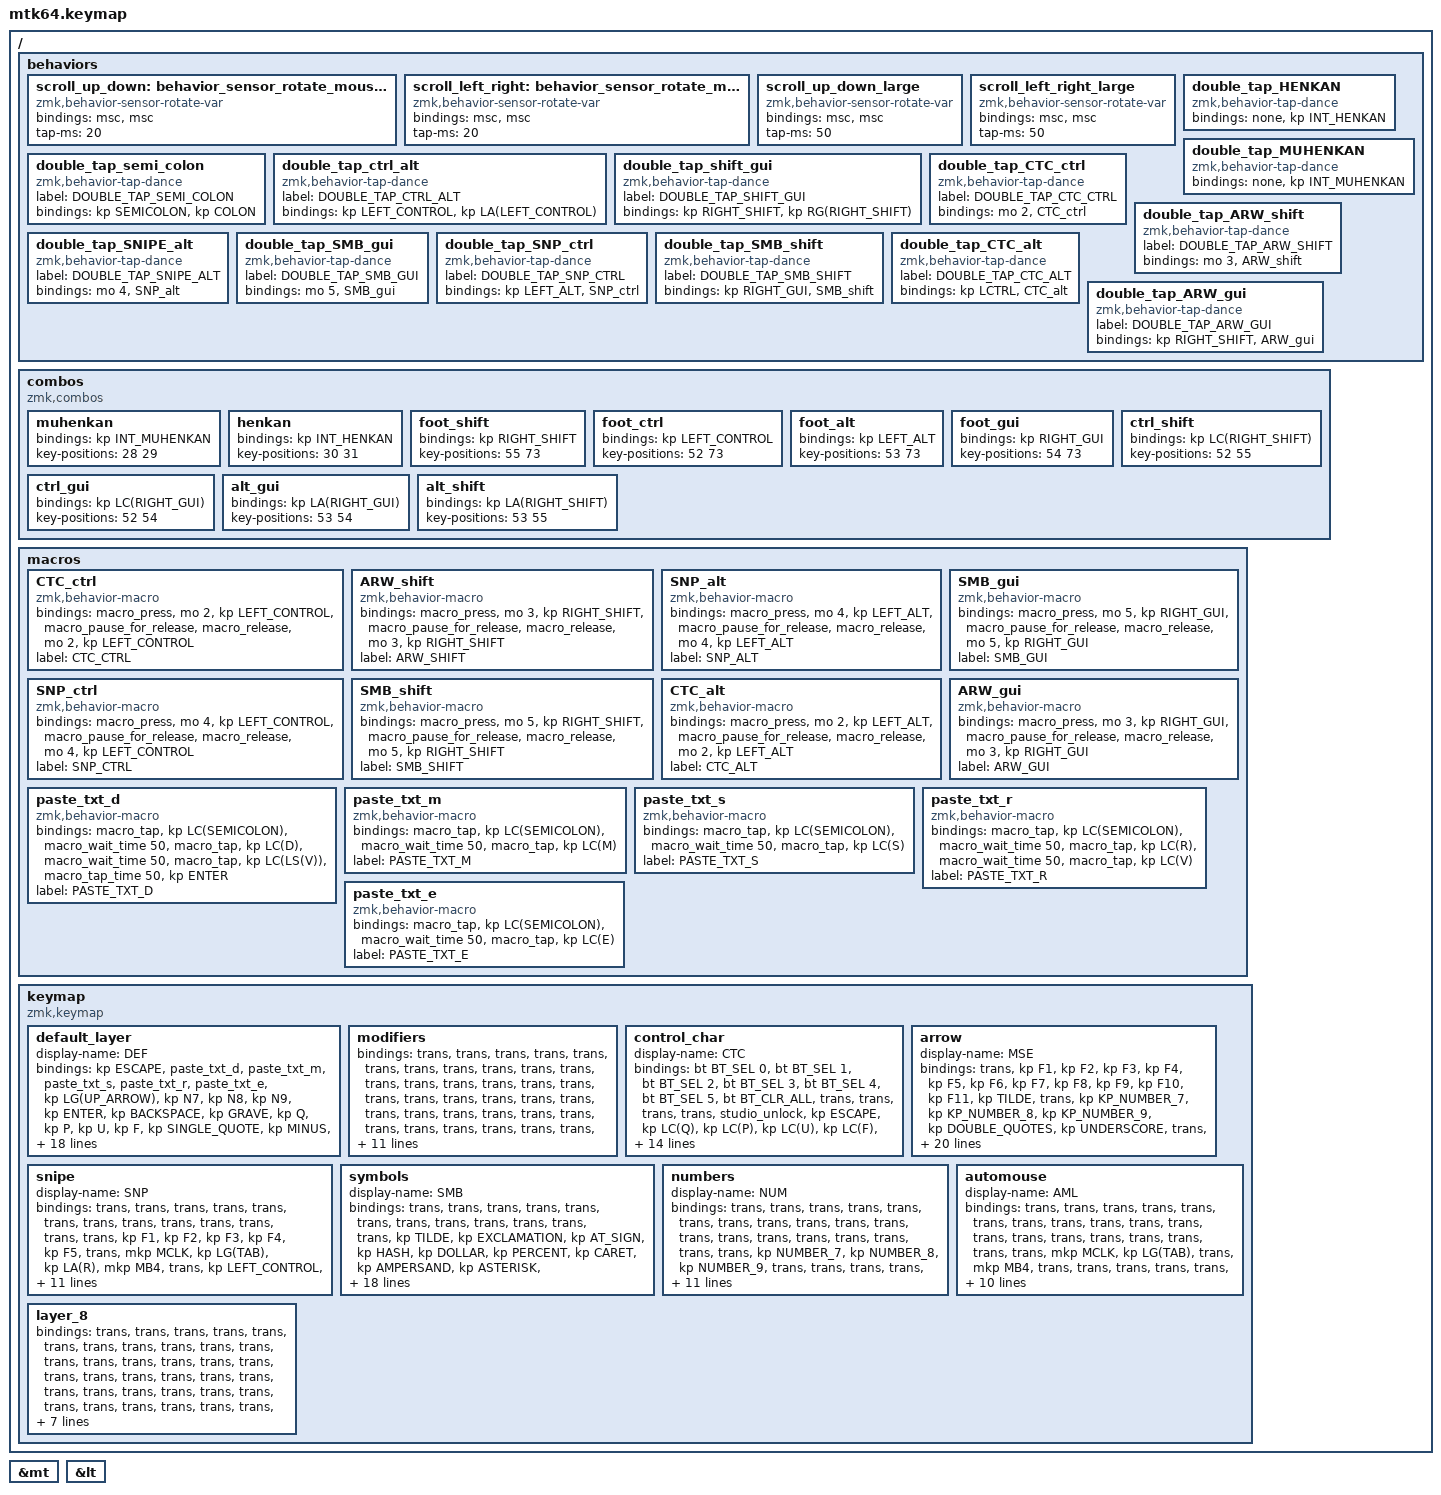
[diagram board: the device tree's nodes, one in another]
#include <input/processors.dtsi>
#include <behaviors.dtsi>
#include <dt-bindings/zmk/bt.h>
#include <dt-bindings/zmk/keys.h>
#include <dt-bindings/zmk/outputs.h>
#include <dt-bindings/zmk/pointing.h>
#include "keycode_japanese.h"

// スクロール量の設定

#define ZMK_POINTING_DEFAULT_SCRL_VAL 100

&mt {
};

&lt {
};

/* &mkp_input_listener { input-processors = <&zip_temp_layer 6 5000>; }; */

/ {
    behaviors {
        // 垂直スクロール用のbehaviorの設定

        scroll_up_down: behavior_sensor_rotate_mouse_wheel_up_down {
            compatible = "zmk,behavior-sensor-rotate-var";
            #sensor-binding-cells = <2>;
            bindings = <&msc>, <&msc>;

            tap-ms = <20>; // スクロールのタップ時間
        };

        // 水平スクロール用のbehaviorの設定

        scroll_left_right: behavior_sensor_rotate_mouse_wheel_left_right {
            compatible = "zmk,behavior-sensor-rotate-var";
            #sensor-binding-cells = <2>;
            bindings = <&msc>, <&msc>;

            tap-ms = <20>; // スクロールのタップ時間
        };

        scroll_up_down_large: scroll_up_down_large {
            compatible = "zmk,behavior-sensor-rotate-var";
            #sensor-binding-cells = <2>;
            bindings = <&msc>, <&msc>;

            tap-ms = <50>;
        };

        scroll_left_right_large: scroll_left_right_large {
            compatible = "zmk,behavior-sensor-rotate-var";
            #sensor-binding-cells = <2>;
            bindings = <&msc>, <&msc>;

            tap-ms = <50>;
        };

        double_tap_HENKAN: double_tap_HENKAN {
            compatible = "zmk,behavior-tap-dance";
            #binding-cells = <0>;
            bindings = <&none>, <&kp INT_HENKAN>;
        };

        double_tap_MUHENKAN: double_tap_MUHENKAN {
            compatible = "zmk,behavior-tap-dance";
            #binding-cells = <0>;
            bindings = <&none>, <&kp INT_MUHENKAN>;
        };

        double_tap_semi_colon: double_tap_semi_colon {
            compatible = "zmk,behavior-tap-dance";
            label = "DOUBLE_TAP_SEMI_COLON";
            #binding-cells = <0>;
            bindings = <&kp SEMICOLON>, <&kp COLON>;
        };

        // The same finger (Press the modifier keys on the same hand at the same time)

        double_tap_ctrl_alt: double_tap_ctrl_alt {
            compatible = "zmk,behavior-tap-dance";
            label = "DOUBLE_TAP_CTRL_ALT";
            #binding-cells = <0>;
            bindings = <&kp LEFT_CONTROL>, <&kp LA(LEFT_CONTROL)>;
        };

        // The same finger (Press the modifier keys on the same hand at the same time)

        double_tap_shift_gui: double_tap_shift_gui {
            compatible = "zmk,behavior-tap-dance";
            label = "DOUBLE_TAP_SHIFT_GUI";
            #binding-cells = <0>;
            bindings = <&kp RIGHT_SHIFT>, <&kp RG(RIGHT_SHIFT)>;
        };

        // The same key (Press the modifier key on the layer after moving)

        double_tap_CTC_ctrl: double_tap_CTC_ctrl {
            compatible = "zmk,behavior-tap-dance";
            label = "DOUBLE_TAP_CTC_CTRL";
            #binding-cells = <0>;
            bindings = <&mo 2>, <&CTC_ctrl>;
        };

        // The same key (Press the modifier key on the layer after moving)

        double_tap_ARW_shift: double_tap_ARW_shift {
            compatible = "zmk,behavior-tap-dance";
            label = "DOUBLE_TAP_ARW_SHIFT";
            #binding-cells = <0>;
            bindings = <&mo 3>, <&ARW_shift>;
        };

        // The same key (Press the modifier key on the layer after moving)

        double_tap_SNIPE_alt: double_tap_SNIPE_alt {
            compatible = "zmk,behavior-tap-dance";
            label = "DOUBLE_TAP_SNIPE_ALT";
            #binding-cells = <0>;
            bindings = <&mo 4>, <&SNP_alt>;
        };

        // The same key (Press the modifier key on the layer after moving)

        double_tap_SMB_gui: double_tap_SMB_gui {
            compatible = "zmk,behavior-tap-dance";
            label = "DOUBLE_TAP_SMB_GUI";
            #binding-cells = <0>;
            bindings = <&mo 5>, <&SMB_gui>;
        };

        // The same finger (Press the modifier key on the same hand after moving the layer)

        double_tap_SNP_ctrl: double_tap_SNP_ctrl {
            compatible = "zmk,behavior-tap-dance";
            label = "DOUBLE_TAP_SNP_CTRL";
            #binding-cells = <0>;
            bindings = <&kp LEFT_ALT>, <&SNP_ctrl>;
        };

        // The same finger (Press the modifier key on the same hand after moving the layer)

        double_tap_SMB_shift: double_tap_SMB_shift {
            compatible = "zmk,behavior-tap-dance";
            label = "DOUBLE_TAP_SMB_SHIFT";
            #binding-cells = <0>;
            bindings = <&kp RIGHT_GUI>, <&SMB_shift>;
        };

        // The same finger (Press the modifier key on the same hand after moving the layer)

        double_tap_CTC_alt: double_tap_CTC_alt {
            compatible = "zmk,behavior-tap-dance";
            label = "DOUBLE_TAP_CTC_ALT";
            #binding-cells = <0>;
            bindings = <&kp LCTRL>, <&CTC_alt>;
        };

        // The same finger (Press the modifier key on the same hand after moving the layer)

        double_tap_ARW_gui: double_tap_ARW_gui {
            compatible = "zmk,behavior-tap-dance";
            label = "DOUBLE_TAP_ARW_GUI";
            #binding-cells = <0>;
            bindings = <&kp RIGHT_SHIFT>, <&ARW_gui>;
        };
    };
};

/ {
    combos {
        compatible = "zmk,combos";

        muhenkan {
            bindings = <&kp INT_MUHENKAN>;
            key-positions = <28 29>;
        };

        henkan {
            bindings = <&kp INT_HENKAN>;
            key-positions = <30 31>;
        };

        foot_shift {
            bindings = <&kp RIGHT_SHIFT>;
            key-positions = <55 73>;
        };

        foot_ctrl {
            bindings = <&kp LEFT_CONTROL>;
            key-positions = <52 73>;
        };

        foot_alt {
            bindings = <&kp LEFT_ALT>;
            key-positions = <53 73>;
        };

        foot_gui {
            bindings = <&kp RIGHT_GUI>;
            key-positions = <54 73>;
        };

        ctrl_shift {
            bindings = <&kp LC(RIGHT_SHIFT)>;
            key-positions = <52 55>;
        };

        ctrl_gui {
            bindings = <&kp LC(RIGHT_GUI)>;
            key-positions = <52 54>;
        };

        alt_gui {
            bindings = <&kp LA(RIGHT_GUI)>;
            key-positions = <53 54>;
        };

        alt_shift {
            bindings = <&kp LA(RIGHT_SHIFT)>;
            key-positions = <53 55>;
        };
    };

    macros {
        CTC_ctrl: CTC_ctrl {
            compatible = "zmk,behavior-macro";
            #binding-cells = <0>;
            bindings =
                <&macro_press>,
                <&mo 2 &kp LEFT_CONTROL>,
                <&macro_pause_for_release>,
                <&macro_release>,
                <&mo 2 &kp LEFT_CONTROL>;

            label = "CTC_CTRL";
        };

        ARW_shift: ARW_shift {
            compatible = "zmk,behavior-macro";
            #binding-cells = <0>;
            bindings =
                <&macro_press>,
                <&mo 3 &kp RIGHT_SHIFT>,
                <&macro_pause_for_release>,
                <&macro_release>,
                <&mo 3 &kp RIGHT_SHIFT>;

            label = "ARW_SHIFT";
        };

        SNP_alt: SNP_alt {
            compatible = "zmk,behavior-macro";
            #binding-cells = <0>;
            bindings =
                <&macro_press>,
                <&mo 4 &kp LEFT_ALT>,
                <&macro_pause_for_release>,
                <&macro_release>,
                <&mo 4 &kp LEFT_ALT>;

            label = "SNP_ALT";
        };

        SMB_gui: SMB_gui {
            compatible = "zmk,behavior-macro";
            #binding-cells = <0>;
            bindings =
                <&macro_press>,
                <&mo 5 &kp RIGHT_GUI>,
                <&macro_pause_for_release>,
                <&macro_release>,
                <&mo 5 &kp RIGHT_GUI>;

            label = "SMB_GUI";
        };

        SNP_ctrl: SNP_ctrl {
            compatible = "zmk,behavior-macro";
            #binding-cells = <0>;
            bindings =
                <&macro_press>,
                <&mo 4 &kp LEFT_CONTROL>,
                <&macro_pause_for_release>,
                <&macro_release>,
                <&mo 4 &kp LEFT_CONTROL>;

            label = "SNP_CTRL";
        };

        SMB_shift: SMB_shift {
            compatible = "zmk,behavior-macro";
            #binding-cells = <0>;
            bindings =
                <&macro_press>,
                <&mo 5 &kp RIGHT_SHIFT>,
                <&macro_pause_for_release>,
                <&macro_release>,
                <&mo 5 &kp RIGHT_SHIFT>;

            label = "SMB_SHIFT";
        };

        CTC_alt: CTC_alt {
            compatible = "zmk,behavior-macro";
            #binding-cells = <0>;
            bindings =
                <&macro_press>,
                <&mo 2 &kp LEFT_ALT>,
                <&macro_pause_for_release>,
                <&macro_release>,
                <&mo 2 &kp LEFT_ALT>;

            label = "CTC_ALT";
        };

        ARW_gui: ARW_gui {
            compatible = "zmk,behavior-macro";
            #binding-cells = <0>;
            bindings =
                <&macro_press>,
                <&mo 3 &kp RIGHT_GUI>,
                <&macro_pause_for_release>,
                <&macro_release>,
                <&mo 3 &kp RIGHT_GUI>;

            label = "ARW_GUI";
        };

        paste_txt_d: paste_txt_d {
            compatible = "zmk,behavior-macro";
            #binding-cells = <0>;
            bindings =
                <&macro_tap>,
                <&kp LC(SEMICOLON)>,
                <&macro_wait_time 50>,
                <&macro_tap>,
                <&kp LC(D)>,
                <&macro_wait_time 50>,
                <&macro_tap>,
                <&kp LC(LS(V))>,
                <&macro_tap_time 50>,
                <&kp ENTER>;

            label = "PASTE_TXT_D";
        };

        paste_txt_m: paste_txt_m {
            compatible = "zmk,behavior-macro";
            #binding-cells = <0>;
            bindings =
                <&macro_tap>,
                <&kp LC(SEMICOLON)>,
                <&macro_wait_time 50>,
                <&macro_tap>,
                <&kp LC(M)>;

            label = "PASTE_TXT_M";
        };

        paste_txt_s: paste_txt_s {
            compatible = "zmk,behavior-macro";
            #binding-cells = <0>;
            bindings =
                <&macro_tap>,
                <&kp LC(SEMICOLON)>,
                <&macro_wait_time 50>,
                <&macro_tap>,
                <&kp LC(S)>;

            label = "PASTE_TXT_S";
        };

        paste_txt_r: paste_txt_r {
            compatible = "zmk,behavior-macro";
            #binding-cells = <0>;
            bindings =
                <&macro_tap>,
                <&kp LC(SEMICOLON)>,
                <&macro_wait_time 50>,
                <&macro_tap>,
                <&kp LC(R)>,
                <&macro_wait_time 50>,
                <&macro_tap>,
                <&kp LC(V)>;

            label = "PASTE_TXT_R";
        };

        paste_txt_e: paste_txt_e {
            compatible = "zmk,behavior-macro";
            #binding-cells = <0>;
            bindings =
                <&macro_tap>,
                <&kp LC(SEMICOLON)>,
                <&macro_wait_time 50>,
                <&macro_tap>,
                <&kp LC(E)>;

            label = "PASTE_TXT_E";
        };
    };

    keymap {
        compatible = "zmk,keymap";

        default_layer {
            display-name = "DEF";
            bindings = <
&kp ESCAPE      &paste_txt_d  &paste_txt_m  &paste_txt_s  &paste_txt_r  &paste_txt_e                                                                                                                                 &kp LG(UP_ARROW)  &kp N7  &kp N8  &kp N9  &kp ENTER  &kp BACKSPACE
&kp GRAVE       &kp Q         &kp P         &kp U         &kp F         &kp SINGLE_QUOTE                                                                                                                             &kp MINUS         &kp N   &kp S   &kp R   &kp Y      &kp UNDERSCORE
&kp SPACE       &kp E         &kp I         &kp A         &kp O         &double_tap_semi_colon                                                                                                                       &kp H             &kp J   &kp K   &kp L   &kp T      &kp B
&kp LEFT_SHIFT  &kp Z         &kp X         &kp C         &kp V         &kp COMMA               &kp LG(LEFT_ARROW)                                                                            &kp RG(RIGHT_ARROW)          &kp PERIOD        &kp D   &kp M   &kp G   &kp W      &kp RIGHT_SHIFT
&mo 1           &kp LGUI                                                                        &double_tap_CTC_ctrl  &double_tap_SNIPE_alt                            &double_tap_SMB_gui    &double_tap_ARW_shift                                            &mkp LCLK  &mkp RCLK
                                            &bt BT_PRV    &bt BT_NXT                                                  &kp LC(LEFT_ALT)                                 &kp RS(RIGHT_GUI)                                               &none   &none
                                                                                                                      &mo 5                                            &mo 5
                &mo 2         &mo 6         &mo 5                                                                                                                                                                                              &mo 2   &mo 6   &mo 5
                                                                                                                      &lt (1) LC(LG(LEFT_ARROW))   &lt (1) RG(RC(UP_ARROW))  &lt (1) LC(LG(RIGHT_ARROW))
            >;

            sensor-bindings =
                <&scroll_left_right SCRL_LEFT SCRL_RIGHT>,
                <&scroll_up_down SCRL_UP SCRL_DOWN>;
        };

        modifiers {
            bindings = <
&trans  &trans  &trans  &trans        &trans        &trans                                                                                                           &trans  &trans  &trans  &trans  &trans  &trans
&trans  &trans  &trans  &trans        &trans        &trans                                                                                                           &trans  &trans  &trans  &trans  &trans  &trans
&trans  &trans  &trans  &trans        &trans        &trans                                                                                                           &trans  &trans  &trans  &trans  &trans  &trans
&trans  &trans  &trans  &trans        &trans        &trans  &trans                                                                              &trans               &trans  &trans  &trans  &trans  &trans  &trans
&trans  &trans                                              &double_tap_CTC_alt  &double_tap_SNP_ctrl                    &double_tap_SMB_shift  &double_tap_ARW_gui                                  &trans  &trans
                        &out OUT_USB  &out OUT_BLE                               &trans                                  &trans                                              &trans  &trans
                                                                                 &trans                                  &trans
        &trans  &trans  &trans                                                                                                                                                       &trans  &trans  &trans
                                                                                 &kp LG(UP_ARROW)      &kp LG(UP_ARROW)  &kp RG(UP_ARROW)
            >;

            label = "MDF";
        };

        control_char {
            display-name = "CTC";
            bindings = <
&bt BT_SEL 0      &bt BT_SEL 1  &bt BT_SEL 2  &bt BT_SEL 3  &bt BT_SEL 4  &bt BT_SEL 5                                                                                                      &bt BT_CLR_ALL  &trans      &trans        &trans     &trans     &studio_unlock
&kp ESCAPE        &kp LC(Q)     &kp LC(P)     &kp LC(U)     &kp LC(F)     &trans                                                                                                            &trans          &kp LC(S)   &kp LC(N)     &kp LC(R)  &kp LC(Y)  &kp ESCAPE
&kp LEFT_CONTROL  &kp END       &kp TAB       &kp HOME      &kp LC(O)     &kp LC(SEMICOLON)                                                                                                 &kp BACKSPACE   &kp ENTER   &kp LC(K)     &kp LC(L)  &trans     &trans
&trans            &kp DELETE    &trans        &kp LC(C)     &kp LC(V)     &trans             &trans                                                                    &trans               &trans          &kp ESCAPE  &kp KP_ENTER  &trans     &kp LC(W)  &trans
&trans            &trans                                                                     &double_tap_CTC_alt  &double_tap_SNP_ctrl          &double_tap_SMB_shift  &double_tap_ARW_gui                                                       &trans     &trans
                                              &trans        &trans                                                &kp LS(LEFT_GUI)              &kp RC(RIGHT_ALT)                                           &trans      &trans
                                                                                                                  &trans                        &trans
                  &trans        &trans        &trans                                                                                                                                                                    &trans        &trans     &trans
                                                                                                                  &trans                &trans  &trans
            >;
        };

        arrow {
            display-name = "MSE";
            bindings = <
&trans     &kp F1                        &kp F2                      &kp F3                    &kp F4                    &kp F5                                                                                                            &kp F6          &kp F7          &kp F8        &kp F9           &kp F10          &kp F11
&kp TILDE  &trans                        &kp KP_NUMBER_7             &kp KP_NUMBER_8           &kp KP_NUMBER_9           &kp DOUBLE_QUOTES                                                                                                 &kp UNDERSCORE  &trans          &trans        &trans           &kp PRINTSCREEN  &kp F12
&trans     &trans                        &kp KP_NUMBER_4             &kp KP_NUMBER_5           &kp KP_NUMBER_6           &kp COLON                                                                                                         &kp LEFT_ARROW        &kp DOWN_ARROW  &kp UP_ARROW  &kp RIGHT_ARROW  &trans           &kp PRINTSCREEN
&trans     &mt LEFT_CONTROL KP_NUMBER_0  &mt LEFT_SHIFT KP_NUMBER_1  &mt LEFT_ALT KP_NUMBER_2  &mt LEFT_GUI KP_NUMBER_3  &trans             &trans                                                                    &trans               &trans          &trans          &trans        &trans           &trans           &trans
&trans     &trans                                                                                                                           &double_tap_CTC_alt  &double_tap_SNP_ctrl          &double_tap_SMB_shift  &double_tap_ARW_gui                                                                 &trans           &trans
                                                                     &trans                    &trans                                                            &kp LS(LEFT_GUI)              &kp RC(RIGHT_ALT)                                           &trans          &trans
                                                                                                                                                                 &trans                        &trans
           &trans                        &trans                      &trans                                                                                                                                                                                                &trans        &trans           &trans
                                                                                                                                                                 &trans                &trans  &trans
            >;

            sensor-bindings =
                <&inc_dec_kp LG(LS(TAB)) LG(TAB)>,
                <&inc_dec_kp LA(LS(TAB)) LA(TAB)>;
        };

        snipe {
            display-name = "SNP";
            bindings = <
&trans            &trans   &trans   &trans     &trans     &trans                                                                     &trans                  &trans     &trans       &trans                   &trans    &trans
&trans            &kp F1   &kp F2   &kp F3     &kp F4     &kp F5                                                                     &trans                  &mkp MCLK  &kp LG(TAB)  &kp LA(R)                &mkp MB4  &trans
&kp LEFT_CONTROL  &kp F6   &kp F7   &kp F8     &kp F9     &kp F10                                                                    &kp LC(LG(LEFT_ARROW))  &mkp LCLK  &mkp RCLK    &kp LC(LG(RIGHT_ARROW))  &trans    &trans
&kp LEFT_SHIFT    &kp F11  &kp F12  &kp LC(C)  &kp LC(V)  &trans   &trans                                           &trans           &mkp MB5                &mkp MB4   &trans       &trans                   &trans    &trans
&trans            &trans                                           &kp LEFT_CONTROL  &kp LEFT_ALT    &kp RIGHT_GUI  &kp RIGHT_SHIFT                                                                           &trans    &trans
            >;

            sensor-bindings =
                <&scroll_left_right_large SCRL_LEFT SCRL_RIGHT>,
                <&scroll_up_down_large SCRL_UP SCRL_DOWN>;
        };

        symbols {
            display-name = "SMB";
            bindings = <
&trans     &trans           &trans        &trans        &trans         &trans                                                                                &trans        &trans            &trans             &trans                &trans                 &trans
&kp TILDE  &kp EXCLAMATION  &kp AT_SIGN   &kp HASH      &kp DOLLAR     &kp PERCENT                                                                           &kp CARET     &kp AMPERSAND     &kp ASTERISK       &kp LEFT_PARENTHESIS  &kp RIGHT_PARENTHESIS  &trans
&kp EQUAL  &kp NUMBER_1     &kp NUMBER_2  &kp NUMBER_3  &kp NUMBER_4   &kp NUMBER_5                                                                          &kp NUMBER_6  &kp NUMBER_7      &kp NUMBER_8       &kp NUMBER_9          &kp NUMBER_0           &kp PLUS
&trans     &kp QUESTION     &kp PIPE      &kp SLASH     &kp BACKSLASH  &trans        &trans                                                 &trans           &trans        &kp LEFT_BRACKET  &kp RIGHT_BRACKET  &kp LEFT_BRACE        &kp RIGHT_BRACE        &trans
&trans     &trans                                                                    &kp LEFT_CONTROL  &kp LEFT_ALT          &kp RIGHT_GUI  &kp RIGHT_SHIFT                                                                           &trans                 &trans
                                          &out OUT_USB  &out OUT_BLE                                   &trans                &trans                                        &trans            &trans
                                                                                                       &trans                &trans
           &trans           &trans        &trans                                                                                                                                             &trans             &trans                &trans
                                                                                                       &trans        &trans  &trans
            >;

            sensor-bindings =
                <&inc_dec_kp C_VOLUME_UP C_VOLUME_DOWN>,
                <&inc_dec_kp PAGE_UP PAGE_DOWN>;
        };

        numbers {
            display-name = "NUM";
            bindings = <
&trans  &trans  &trans  &trans  &trans  &trans                                                                          &trans        &trans        &trans        &trans        &trans  &trans
&trans  &trans  &trans  &trans  &trans  &trans                                                                          &trans        &kp NUMBER_7  &kp NUMBER_8  &kp NUMBER_9  &trans  &trans
&trans  &trans  &trans  &trans  &trans  &trans                                                                          &kp PERIOD    &kp NUMBER_4  &kp NUMBER_5  &kp NUMBER_6  &trans  &trans
&trans  &trans  &trans  &trans  &trans  &trans  &trans                                                 &tog 6           &kp NUMBER_0  &kp NUMBER_1  &kp NUMBER_2  &kp NUMBER_3  &trans  &trans
&trans  &trans                                  &kp LEFT_CONTROL  &kp LEFT_ALT          &kp RIGHT_GUI  &kp RIGHT_SHIFT                                                          &trans  &trans
                        &trans  &trans                            &trans                &trans                                        &trans        &trans
                                                                  &trans                &trans
        &trans  &trans  &trans                                                                                                                      &trans        &trans        &trans
                                                                  &trans        &trans  &trans
            >;
        };

        automouse {
            display-name = "AML";
            bindings = <
&trans  &trans  &trans  &trans  &trans  &trans                                                                         &trans                  &trans     &trans       &trans             &trans    &trans
&trans  &trans  &trans  &trans  &trans  &trans                                                                         &trans                  &mkp MCLK  &kp LG(TAB)  &trans             &mkp MB4  &trans
&trans  &trans  &trans  &trans  &trans  &trans                                                                         &kp LC(LG(LEFT_ARROW))  &mkp LCLK  &mkp RCLK    &kp LC(LG(RIGHT_ARROW))  &trans    &trans
&trans  &trans  &trans  &trans  &trans  &trans  &trans                                                 &trans          &mkp MB5                &trans     &trans       &trans             &trans    &trans
&trans  &trans                                  &kp LEFT_CONTROL  &kp LEFT_ALT          &kp RIGHT_GUI  &kp LEFT_SHIFT                                                                     &trans    &trans
                        &trans  &trans                            &trans                &trans                                                 &trans     &trans
                                                                  &trans                &trans
        &trans  &trans  &trans                                                                                                                            &trans       &trans             &trans
                                                                  &trans        &trans  &trans
            >;
        };

        layer_8 {
            bindings = <
&trans  &trans  &trans  &trans  &trans  &trans                                          &trans  &trans  &trans  &trans  &trans  &trans
&trans  &trans  &trans  &trans  &trans  &trans                                          &trans  &trans  &trans  &trans  &trans  &trans
&trans  &trans  &trans  &trans  &trans  &trans                                          &trans  &trans  &trans  &trans  &trans  &trans
&trans  &trans  &trans  &trans  &trans  &trans  &trans                          &trans  &trans  &trans  &trans  &trans  &trans  &trans
&trans  &trans                                  &trans  &trans          &trans  &trans                                  &trans  &trans
                        &trans  &trans                  &trans          &trans                  &trans  &trans
                                                        &trans          &trans
        &trans  &trans  &trans                                                                          &trans  &trans  &trans
                                                        &trans  &trans  &trans
            >;
        };
    };
};
